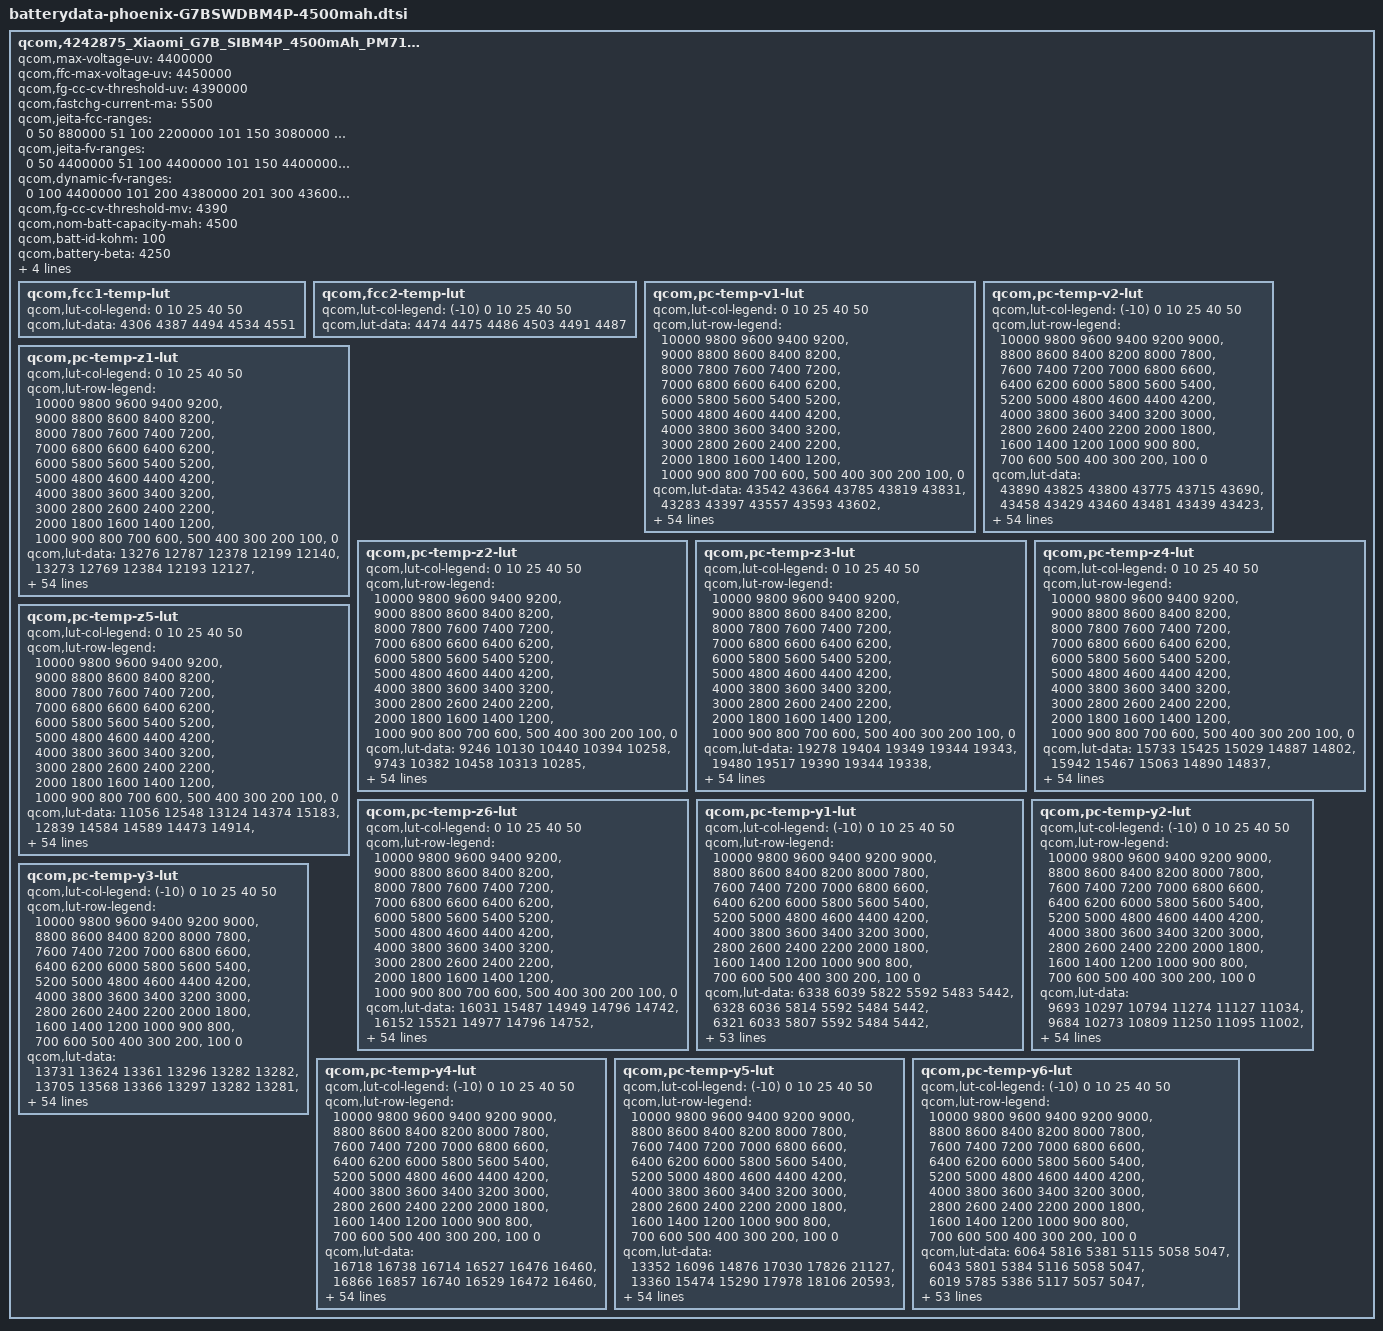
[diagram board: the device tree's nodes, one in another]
qcom,4242875_Xiaomi_G7B_SIBM4P_4500mAh_PM7150 {
	/* 4242875_Xiaomi_G7B_SIBM4P_4500mAh_PM7150_averaged_MasterSlave_Oct16th2019 */
	qcom,max-voltage-uv = <4400000>;
	qcom,ffc-max-voltage-uv = <4450000>;
	qcom,fg-cc-cv-threshold-uv = <4390000>;
	qcom,fastchg-current-ma = <5500>;
	qcom,jeita-fcc-ranges = <0  50  880000
				51  100  2200000
				101 150  3080000
				151 450  5500000
				451 580  2200000>;
	qcom,jeita-fv-ranges = <0   50  4400000
				51  100  4400000
				101 150  4400000
				151 450  4450000
				451 580  4100000>;
	qcom,dynamic-fv-ranges = <0    100  4400000
				101  200  4380000
				201  300  4360000
				301  400  4340000
				401  500  4340000>;
	qcom,fg-cc-cv-threshold-mv = <4390>;
	qcom,nom-batt-capacity-mah = <4500>;
	qcom,batt-id-kohm = <100>;
	qcom,battery-beta = <4250>;
	qcom,battery-therm-kohm = <100>;
	qcom,battery-type = "G7BSWDBM4P_4500mAh";
	qcom,qg-batt-profile-ver = <100>;
	mi,six-pin-battery;

	qcom,fcc1-temp-lut {
		qcom,lut-col-legend = <0 10 25 40 50>;
		qcom,lut-data = <4306 4387 4494 4534 4551>;
	};

	qcom,fcc2-temp-lut {
		qcom,lut-col-legend = <(-10) 0 10 25 40 50>;
		qcom,lut-data = <4474 4475 4486 4503 4491 4487>;
	};

	qcom,pc-temp-v1-lut {
		qcom,lut-col-legend = <0 10 25 40 50>;
		qcom,lut-row-legend = <10000 9800 9600 9400 9200>,
			<9000 8800 8600 8400 8200>,
			<8000 7800 7600 7400 7200>,
			<7000 6800 6600 6400 6200>,
			<6000 5800 5600 5400 5200>,
			<5000 4800 4600 4400 4200>,
			<4000 3800 3600 3400 3200>,
			<3000 2800 2600 2400 2200>,
			<2000 1800 1600 1400 1200>,
			<1000 900 800 700 600>,
			<500 400 300 200 100>,
			<0>;
		qcom,lut-data = <43542 43664 43785 43819 43831>,
			<43283 43397 43557 43593 43602>,
			<43023 43145 43301 43356 43370>,
			<42774 42905 43054 43118 43135>,
			<42543 42672 42815 42880 42901>,
			<42322 42440 42579 42642 42666>,
			<42109 42214 42345 42407 42433>,
			<41904 41997 42114 42173 42201>,
			<41707 41788 41888 41943 41970>,
			<41518 41585 41667 41715 41741>,
			<41337 41396 41453 41490 41514>,
			<41144 41210 41254 41271 41292>,
			<40932 41008 41060 41056 41073>,
			<40707 40787 40846 40847 40862>,
			<40457 40556 40605 40639 40657>,
			<40167 40305 40375 40437 40460>,
			<39932 40049 40169 40245 40271>,
			<39796 39875 39982 40063 40088>,
			<39694 39774 39831 39892 39913>,
			<39588 39678 39713 39742 39755>,
			<39483 39530 39577 39587 39596>,
			<39371 39341 39362 39388 39400>,
			<39227 39151 39117 39155 39168>,
			<39051 38939 38936 38961 38969>,
			<38893 38752 38794 38807 38812>,
			<38755 38656 38678 38675 38677>,
			<38636 38597 38586 38561 38561>,
			<38559 38544 38509 38462 38459>,
			<38508 38488 38433 38373 38367>,
			<38465 38435 38359 38292 38282>,
			<38425 38387 38293 38220 38206>,
			<38389 38341 38234 38156 38137>,
			<38355 38299 38183 38100 38076>,
			<38325 38259 38137 38048 38018>,
			<38296 38223 38100 38003 37966>,
			<38268 38189 38061 37958 37914>,
			<38241 38161 38024 37912 37860>,
			<38206 38126 37983 37863 37802>,
			<38152 38065 37925 37799 37731>,
			<38078 37971 37840 37714 37639>,
			<37992 37864 37738 37613 37533>,
			<37875 37738 37619 37496 37417>,
			<37735 37595 37480 37360 37285>,
			<37559 37427 37317 37199 37119>,
			<37393 37287 37173 37065 36989>,
			<37283 37218 37077 36979 36914>,
			<37246 37182 37054 36953 36891>,
			<37213 37156 37034 36938 36874>,
			<37183 37128 37020 36919 36854>,
			<37130 37077 36971 36861 36782>,
			<36913 36844 36716 36588 36480>,
			<36460 36391 36276 36143 36035>,
			<35875 35804 35691 35559 35450>,
			<35079 35004 34890 34760 34644>,
			<33819 33739 33631 33509 33380>,
			<30000 30000 30000 30000 30000>;
	};

	qcom,pc-temp-v2-lut {
		qcom,lut-col-legend = <(-10) 0 10 25 40 50>;
		qcom,lut-row-legend = <10000 9800 9600 9400 9200 9000>,
			<8800 8600 8400 8200 8000 7800>,
			<7600 7400 7200 7000 6800 6600>,
			<6400 6200 6000 5800 5600 5400>,
			<5200 5000 4800 4600 4400 4200>,
			<4000 3800 3600 3400 3200 3000>,
			<2800 2600 2400 2200 2000 1800>,
			<1600 1400 1200 1000 900 800>,
			<700 600 500 400 300 200>,
			<100 0>;
		qcom,lut-data = <43890 43825 43800 43775 43715 43690>,
			<43458 43429 43460 43481 43439 43423>,
			<43070 43068 43145 43203 43174 43165>,
			<42731 42744 42860 42941 42922 42916>,
			<42431 42450 42602 42696 42681 42676>,
			<42162 42188 42354 42457 42444 42440>,
			<41917 41967 42108 42219 42209 42206>,
			<41694 41765 41868 41984 41977 41974>,
			<41499 41541 41622 41755 41748 41745>,
			<41317 41282 41361 41532 41523 41519>,
			<41159 41076 41143 41314 41301 41295>,
			<41043 40975 41000 41105 41083 41078>,
			<40930 40893 40874 40900 40868 40863>,
			<40701 40700 40670 40687 40659 40657>,
			<40157 40199 40325 40464 40453 40455>,
			<39667 39766 40023 40248 40256 40261>,
			<39447 39610 39854 40036 40073 40078>,
			<39286 39502 39717 39837 39900 39902>,
			<39111 39354 39555 39677 39733 39733>,
			<38920 39150 39367 39551 39580 39576>,
			<38746 38931 39174 39408 39413 39406>,
			<38601 38703 38971 39189 39192 39189>,
			<38474 38479 38769 38944 38954 38953>,
			<38377 38335 38594 38754 38765 38766>,
			<38303 38241 38441 38598 38610 38613>,
			<38238 38170 38305 38464 38478 38482>,
			<38177 38114 38178 38350 38366 38369>,
			<38120 38067 38067 38250 38268 38269>,
			<38066 38024 37997 38160 38179 38178>,
			<38016 37983 37955 38078 38098 38093>,
			<37967 37945 37919 38005 38025 38017>,
			<37917 37908 37881 37934 37959 37950>,
			<37867 37870 37845 37870 37899 37890>,
			<37814 37831 37811 37817 37836 37825>,
			<37761 37790 37782 37773 37771 37755>,
			<37705 37746 37747 37728 37700 37678>,
			<37643 37697 37705 37679 37619 37579>,
			<37578 37642 37652 37626 37530 37469>,
			<37504 37576 37585 37560 37448 37378>,
			<37418 37496 37493 37479 37375 37305>,
			<37327 37404 37387 37387 37295 37229>,
			<37236 37296 37270 37280 37196 37131>,
			<37146 37175 37146 37159 37081 37016>,
			<37067 37052 37035 37016 36938 36876>,
			<36990 36937 36933 36907 36833 36777>,
			<36906 36849 36831 36850 36795 36739>,
			<36856 36811 36776 36834 36781 36729>,
			<36795 36768 36724 36810 36767 36711>,
			<36712 36715 36653 36770 36732 36675>,
			<36574 36619 36544 36674 36626 36539>,
			<36329 36409 36324 36397 36294 36173>,
			<35936 35996 35912 35895 35789 35654>,
			<35351 35372 35297 35233 35131 34976>,
			<34490 34490 34421 34324 34230 34043>,
			<33013 33050 32977 32889 32871 32634>,
			<28664 28265 27951 27826 28122 27845>;
	};

	qcom,pc-temp-z1-lut {
		qcom,lut-col-legend = <0 10 25 40 50>;
		qcom,lut-row-legend = <10000 9800 9600 9400 9200>,
			<9000 8800 8600 8400 8200>,
			<8000 7800 7600 7400 7200>,
			<7000 6800 6600 6400 6200>,
			<6000 5800 5600 5400 5200>,
			<5000 4800 4600 4400 4200>,
			<4000 3800 3600 3400 3200>,
			<3000 2800 2600 2400 2200>,
			<2000 1800 1600 1400 1200>,
			<1000 900 800 700 600>,
			<500 400 300 200 100>,
			<0>;
		qcom,lut-data = <13276 12787 12378 12199 12140>,
			<13273 12769 12384 12193 12127>,
			<13254 12761 12373 12177 12116>,
			<13239 12756 12365 12165 12107>,
			<13235 12752 12355 12158 12101>,
			<13231 12743 12349 12153 12096>,
			<13225 12733 12344 12148 12092>,
			<13215 12728 12338 12143 12088>,
			<13205 12726 12337 12141 12085>,
			<13196 12724 12335 12140 12084>,
			<13186 12718 12334 12139 12083>,
			<13174 12709 12337 12140 12082>,
			<13149 12695 12344 12142 12082>,
			<13117 12672 12341 12142 12082>,
			<13098 12655 12315 12135 12081>,
			<13082 12652 12298 12126 12081>,
			<13069 12652 12301 12126 12081>,
			<13053 12654 12307 12130 12083>,
			<13036 12665 12310 12133 12084>,
			<13031 12675 12313 12136 12085>,
			<13037 12677 12315 12138 12086>,
			<13044 12676 12320 12140 12086>,
			<13049 12678 12324 12142 12086>,
			<13055 12685 12325 12143 12086>,
			<13060 12693 12324 12144 12088>,
			<13067 12698 12324 12145 12092>,
			<13076 12702 12330 12147 12095>,
			<13081 12704 12341 12150 12098>,
			<13084 12700 12345 12153 12101>,
			<13084 12693 12346 12157 12105>,
			<13078 12693 12348 12161 12108>,
			<13071 12699 12350 12166 12112>,
			<13069 12705 12352 12170 12115>,
			<13079 12712 12355 12174 12119>,
			<13091 12722 12360 12177 12123>,
			<13098 12724 12364 12180 12126>,
			<13104 12721 12367 12184 12130>,
			<13111 12718 12369 12189 12133>,
			<13120 12723 12372 12193 12137>,
			<13132 12734 12378 12196 12142>,
			<13144 12747 12381 12198 12145>,
			<13157 12768 12382 12200 12146>,
			<13175 12777 12383 12202 12147>,
			<13200 12765 12384 12209 12150>,
			<13200 12768 12391 12211 12152>,
			<13202 12774 12394 12211 12153>,
			<13188 12765 12391 12217 12154>,
			<13202 12768 12396 12212 12157>,
			<13190 12771 12392 12218 12159>,
			<13183 12789 12404 12220 12164>,
			<13205 12801 12408 12229 12171>,
			<13209 12789 12412 12234 12175>,
			<13222 12805 12423 12238 12185>,
			<13253 12849 12449 12250 12195>,
			<13253 12849 12449 12250 12195>,
			<13253 12849 12449 12250 12195>;
	};

	qcom,pc-temp-z2-lut {
		qcom,lut-col-legend = <0 10 25 40 50>;
		qcom,lut-row-legend = <10000 9800 9600 9400 9200>,
			<9000 8800 8600 8400 8200>,
			<8000 7800 7600 7400 7200>,
			<7000 6800 6600 6400 6200>,
			<6000 5800 5600 5400 5200>,
			<5000 4800 4600 4400 4200>,
			<4000 3800 3600 3400 3200>,
			<3000 2800 2600 2400 2200>,
			<2000 1800 1600 1400 1200>,
			<1000 900 800 700 600>,
			<500 400 300 200 100>,
			<0>;
		qcom,lut-data = <9246 10130 10440 10394 10258>,
			<9743 10382 10458 10313 10285>,
			<10020 10406 10510 10375 10293>,
			<10186 10395 10520 10407 10299>,
			<10178 10383 10508 10390 10259>,
			<10161 10367 10492 10365 10182>,
			<10145 10347 10468 10345 10160>,
			<10128 10328 10442 10317 10159>,
			<10115 10307 10426 10291 10159>,
			<10112 10296 10414 10261 10150>,
			<10110 10301 10409 10235 10135>,
			<10109 10309 10411 10232 10137>,
			<10103 10312 10415 10233 10156>,
			<10097 10308 10425 10235 10167>,
			<10097 10305 10451 10229 10172>,
			<10102 10316 10467 10222 10185>,
			<10108 10341 10446 10226 10199>,
			<10120 10360 10412 10233 10216>,
			<10139 10371 10409 10243 10233>,
			<10158 10383 10431 10266 10252>,
			<10179 10405 10465 10304 10278>,
			<10200 10436 10544 10395 10325>,
			<10220 10451 10634 10549 10403>,
			<10238 10451 10639 10597 10435>,
			<10253 10448 10580 10482 10402>,
			<10265 10447 10543 10368 10363>,
			<10275 10444 10565 10412 10362>,
			<10285 10444 10598 10535 10372>,
			<10294 10452 10602 10570 10369>,
			<10303 10463 10585 10479 10262>,
			<10313 10470 10568 10390 10152>,
			<10324 10477 10555 10375 10148>,
			<10334 10484 10545 10366 10160>,
			<10342 10493 10544 10364 10175>,
			<10352 10503 10553 10358 10213>,
			<10364 10513 10566 10355 10263>,
			<10380 10523 10590 10393 10316>,
			<10392 10535 10623 10469 10372>,
			<10346 10552 10653 10511 10409>,
			<10270 10574 10686 10538 10437>,
			<10245 10586 10705 10553 10451>,
			<10206 10590 10700 10571 10446>,
			<10205 10596 10690 10589 10435>,
			<10308 10615 10690 10559 10422>,
			<10325 10729 10725 10533 10420>,
			<10264 12427 10738 10528 10390>,
			<10352 13610 10724 10514 10405>,
			<10335 24514 10727 10514 10436>,
			<10337 25623 10672 10546 10467>,
			<10253 30523 10765 10648 10590>,
			<10135 31150 10762 10507 10360>,
			<9996 22497 10725 10388 10261>,
			<9876 20729 10669 10368 10202>,
			<9706 16198 10668 10326 10167>,
			<9706 16198 10668 10326 10167>,
			<9706 16198 10668 10326 10167>;
	};

	qcom,pc-temp-z3-lut {
		qcom,lut-col-legend = <0 10 25 40 50>;
		qcom,lut-row-legend = <10000 9800 9600 9400 9200>,
			<9000 8800 8600 8400 8200>,
			<8000 7800 7600 7400 7200>,
			<7000 6800 6600 6400 6200>,
			<6000 5800 5600 5400 5200>,
			<5000 4800 4600 4400 4200>,
			<4000 3800 3600 3400 3200>,
			<3000 2800 2600 2400 2200>,
			<2000 1800 1600 1400 1200>,
			<1000 900 800 700 600>,
			<500 400 300 200 100>,
			<0>;
		qcom,lut-data = <19278 19404 19349 19344 19343>,
			<19480 19517 19390 19344 19338>,
			<19640 19554 19439 19369 19358>,
			<19734 19572 19453 19387 19376>,
			<19747 19581 19455 19393 19381>,
			<19755 19586 19456 19397 19384>,
			<19756 19589 19455 19397 19385>,
			<19752 19589 19454 19397 19385>,
			<19746 19585 19453 19398 19385>,
			<19739 19580 19453 19396 19383>,
			<19730 19574 19453 19393 19381>,
			<19724 19567 19449 19392 19379>,
			<19717 19563 19444 19390 19377>,
			<19711 19557 19441 19388 19375>,
			<19715 19553 19440 19383 19371>,
			<19729 19552 19438 19378 19366>,
			<19739 19549 19434 19376 19363>,
			<19727 19544 19428 19373 19361>,
			<19702 19532 19421 19371 19359>,
			<19684 19520 19413 19365 19354>,
			<19671 19523 19409 19360 19350>,
			<19663 19534 19415 19363 19352>,
			<19667 19539 19425 19373 19360>,
			<19682 19539 19425 19376 19364>,
			<19690 19537 19412 19365 19360>,
			<19689 19534 19404 19355 19356>,
			<19688 19528 19408 19367 19363>,
			<19685 19525 19415 19398 19386>,
			<19677 19526 19423 19408 19395>,
			<19669 19527 19436 19407 19391>,
			<19662 19528 19443 19404 19385>,
			<19655 19529 19442 19400 19380>,
			<19649 19530 19439 19393 19374>,
			<19643 19529 19435 19386 19369>,
			<19638 19528 19429 19380 19362>,
			<19632 19525 19424 19374 19357>,
			<19625 19521 19420 19370 19353>,
			<19619 19516 19416 19366 19350>,
			<19551 19512 19413 19364 19349>,
			<19453 19508 19410 19362 19351>,
			<19411 19504 19407 19361 19352>,
			<19302 19500 19405 19362 19351>,
			<19261 19495 19402 19363 19350>,
			<19261 19486 19397 19362 19355>,
			<19260 19395 19386 19355 19353>,
			<19261 19259 19380 19344 19342>,
			<19260 19258 19373 19343 19333>,
			<19260 19256 19372 19336 19330>,
			<19260 19256 19357 19334 19324>,
			<19261 19256 19351 19328 19321>,
			<19261 19256 19363 19345 19348>,
			<19262 19257 19353 19352 19347>,
			<19263 19256 19353 19352 19346>,
			<19265 19257 19345 19350 19348>,
			<19265 19257 19345 19350 19348>,
			<19265 19257 19345 19350 19348>;
	};

	qcom,pc-temp-z4-lut {
		qcom,lut-col-legend = <0 10 25 40 50>;
		qcom,lut-row-legend = <10000 9800 9600 9400 9200>,
			<9000 8800 8600 8400 8200>,
			<8000 7800 7600 7400 7200>,
			<7000 6800 6600 6400 6200>,
			<6000 5800 5600 5400 5200>,
			<5000 4800 4600 4400 4200>,
			<4000 3800 3600 3400 3200>,
			<3000 2800 2600 2400 2200>,
			<2000 1800 1600 1400 1200>,
			<1000 900 800 700 600>,
			<500 400 300 200 100>,
			<0>;
		qcom,lut-data = <15733 15425 15029 14887 14802>,
			<15942 15467 15063 14890 14837>,
			<15769 15427 15043 14879 14832>,
			<15585 15272 15011 14864 14825>,
			<15445 15137 14951 14842 14811>,
			<15317 15055 14896 14815 14791>,
			<15215 14988 14861 14794 14774>,
			<15133 14937 14832 14776 14759>,
			<15066 14895 14808 14759 14745>,
			<15013 14861 14786 14743 14730>,
			<14969 14834 14768 14730 14718>,
			<14932 14812 14751 14723 14710>,
			<14894 14790 14737 14718 14705>,
			<14866 14767 14730 14714 14701>,
			<14865 14753 14728 14709 14697>,
			<14879 14761 14728 14704 14693>,
			<14888 14778 14724 14697 14688>,
			<14870 14781 14715 14689 14683>,
			<14830 14750 14708 14683 14678>,
			<14800 14719 14696 14679 14674>,
			<14776 14723 14690 14676 14671>,
			<14762 14744 14722 14691 14682>,
			<14766 14770 14780 14737 14728>,
			<14786 14826 14815 14772 14760>,
			<14803 14880 14841 14797 14774>,
			<14825 14882 14852 14812 14783>,
			<14849 14865 14840 14795 14771>,
			<14852 14845 14814 14748 14730>,
			<14841 14828 14791 14722 14706>,
			<14828 14811 14768 14713 14701>,
			<14816 14796 14752 14707 14697>,
			<14804 14783 14745 14703 14692>,
			<14792 14772 14740 14700 14688>,
			<14782 14765 14736 14699 14686>,
			<14772 14759 14734 14699 14685>,
			<14761 14753 14733 14699 14685>,
			<14750 14745 14732 14699 14686>,
			<14744 14740 14731 14701 14688>,
			<14803 14740 14731 14703 14691>,
			<14895 14740 14732 14707 14696>,
			<14933 14739 14733 14710 14699>,
			<15032 14730 14725 14703 14694>,
			<15063 14719 14714 14693 14687>,
			<15040 14709 14708 14693 14688>,
			<14959 14753 14689 14685 14680>,
			<14935 14861 14670 14669 14662>,
			<14927 14855 14664 14662 14659>,
			<14922 14845 14654 14651 14645>,
			<14915 14839 14654 14635 14631>,
			<14908 14835 14655 14637 14628>,
			<14912 14843 14665 14650 14644>,
			<14931 14853 14680 14651 14652>,
			<14937 14855 14680 14652 14655>,
			<14948 14860 14690 14656 14653>,
			<14948 14860 14690 14656 14653>,
			<14948 14860 14690 14656 14653>;
	};

	qcom,pc-temp-z5-lut {
		qcom,lut-col-legend = <0 10 25 40 50>;
		qcom,lut-row-legend = <10000 9800 9600 9400 9200>,
			<9000 8800 8600 8400 8200>,
			<8000 7800 7600 7400 7200>,
			<7000 6800 6600 6400 6200>,
			<6000 5800 5600 5400 5200>,
			<5000 4800 4600 4400 4200>,
			<4000 3800 3600 3400 3200>,
			<3000 2800 2600 2400 2200>,
			<2000 1800 1600 1400 1200>,
			<1000 900 800 700 600>,
			<500 400 300 200 100>,
			<0>;
		qcom,lut-data = <11056 12548 13124 14374 15183>,
			<12839 14584 14589 14473 14914>,
			<14257 15825 16650 16270 17035>,
			<15340 16682 17658 17735 19058>,
			<16015 17518 18133 18382 19680>,
			<16561 18451 18535 18866 20077>,
			<17061 19358 18951 19297 20433>,
			<17511 20170 19405 19668 20801>,
			<17955 20938 20032 20046 21216>,
			<18525 21699 20904 20521 21858>,
			<19218 22565 21841 21031 22639>,
			<19655 23502 22707 21545 23287>,
			<19879 24510 23644 22147 23906>,
			<20215 26451 25049 22643 24219>,
			<21289 27848 27322 23160 24159>,
			<24199 27457 28586 23576 24053>,
			<26149 26479 27334 23678 24331>,
			<25546 26159 25369 23828 25450>,
			<24357 26639 25355 24164 26439>,
			<24031 27599 27623 24994 26967>,
			<24855 32686 30482 26155 27445>,
			<26480 44533 34092 27699 28148>,
			<31615 49587 37537 29601 29101>,
			<43051 46103 36541 29851 29359>,
			<49604 40932 28106 23819 24315>,
			<49892 36972 22357 17913 18468>,
			<48873 32431 22027 18919 18997>,
			<47154 30078 21862 22615 22551>,
			<43944 30060 22425 25555 25044>,
			<41044 30492 25895 27659 26148>,
			<39522 31334 29602 29386 27039>,
			<38371 33268 32362 30804 28112>,
			<37598 35492 34685 31976 29198>,
			<37058 37876 35783 32505 29775>,
			<36769 40303 36457 32765 30134>,
			<36702 41356 36728 32884 30340>,
			<36534 41818 36568 32582 30148>,
			<36419 42041 36158 31713 29535>,
			<33133 41928 35342 30536 28806>,
			<28219 41556 33241 28320 27762>,
			<25414 41095 31317 26654 26806>,
			<15223 39883 30372 26631 26069>,
			<11445 38160 29493 26920 25532>,
			<11459 35250 27773 26361 28019>,
			<11704 27193 28265 25056 28511>,
			<11738 11862 29748 22822 24185>,
			<11676 11811 27179 23192 20990>,
			<11667 11718 28492 22529 22454>,
			<11652 11698 22827 26082 25283>,
			<11679 11734 21687 23301 25607>,
			<11737 11738 22078 23239 29134>,
			<11637 11662 17741 22891 23789>,
			<11563 11576 17279 21759 20939>,
			<11472 11486 15810 19442 19552>,
			<11472 11486 15810 19442 19552>,
			<11472 11486 15810 19442 19552>;
	};

	qcom,pc-temp-z6-lut {
		qcom,lut-col-legend = <0 10 25 40 50>;
		qcom,lut-row-legend = <10000 9800 9600 9400 9200>,
			<9000 8800 8600 8400 8200>,
			<8000 7800 7600 7400 7200>,
			<7000 6800 6600 6400 6200>,
			<6000 5800 5600 5400 5200>,
			<5000 4800 4600 4400 4200>,
			<4000 3800 3600 3400 3200>,
			<3000 2800 2600 2400 2200>,
			<2000 1800 1600 1400 1200>,
			<1000 900 800 700 600>,
			<500 400 300 200 100>,
			<0>;
		qcom,lut-data = <16031 15487 14949 14796 14742>,
			<16152 15521 14977 14796 14752>,
			<16081 15498 14981 14799 14758>,
			<15995 15410 14976 14800 14762>,
			<15907 15329 14945 14793 14759>,
			<15811 15277 14913 14781 14750>,
			<15732 15232 14893 14771 14743>,
			<15668 15194 14877 14762 14736>,
			<15613 15162 14863 14754 14729>,
			<15565 15134 14851 14745 14722>,
			<15523 15110 14841 14738 14716>,
			<15482 15089 14831 14734 14711>,
			<15432 15065 14821 14731 14707>,
			<15391 15034 14814 14728 14704>,
			<15379 15015 14807 14721 14700>,
			<15375 15015 14802 14714 14695>,
			<15370 15017 14798 14710 14691>,
			<15349 15015 14793 14706 14688>,
			<15313 14999 14788 14702 14684>,
			<15290 14984 14780 14697 14680>,
			<15275 14989 14777 14694 14676>,
			<15266 15006 14795 14703 14682>,
			<15271 15025 14827 14729 14707>,
			<15290 15051 14840 14743 14722>,
			<15306 15073 14846 14749 14727>,
			<15318 15074 14848 14752 14730>,
			<15329 15065 14845 14751 14729>,
			<15330 15057 14840 14748 14725>,
			<15323 15052 14836 14745 14720>,
			<15315 15047 14834 14742 14716>,
			<15309 15044 14832 14738 14712>,
			<15302 15040 14830 14734 14708>,
			<15297 15038 14828 14730 14704>,
			<15292 15037 14825 14727 14700>,
			<15289 15036 14823 14723 14697>,
			<15287 15036 14821 14721 14694>,
			<15285 15035 14821 14720 14693>,
			<15284 15034 14820 14719 14692>,
			<15286 15035 14820 14719 14693>,
			<15289 15040 14821 14721 14696>,
			<15290 15042 14822 14722 14698>,
			<15292 15042 14820 14720 14696>,
			<15296 15042 14816 14718 14694>,
			<15303 15041 14813 14718 14697>,
			<15289 15027 14803 14711 14693>,
			<15281 15010 14794 14699 14679>,
			<15279 15007 14789 14696 14673>,
			<15278 15005 14785 14688 14666>,
			<15278 15005 14778 14680 14657>,
			<15283 15009 14779 14679 14655>,
			<15295 15019 14793 14696 14678>,
			<15312 15031 14798 14702 14683>,
			<15328 15041 14802 14705 14686>,
			<15352 15057 14809 14709 14690>,
			<15352 15057 14809 14709 14690>,
			<15352 15057 14809 14709 14690>;
	};

	qcom,pc-temp-y1-lut {
		qcom,lut-col-legend = <(-10) 0 10 25 40 50>;
		qcom,lut-row-legend = <10000 9800 9600 9400 9200 9000>,
			<8800 8600 8400 8200 8000 7800>,
			<7600 7400 7200 7000 6800 6600>,
			<6400 6200 6000 5800 5600 5400>,
			<5200 5000 4800 4600 4400 4200>,
			<4000 3800 3600 3400 3200 3000>,
			<2800 2600 2400 2200 2000 1800>,
			<1600 1400 1200 1000 900 800>,
			<700 600 500 400 300 200>,
			<100 0>;
		qcom,lut-data = <6338 6039 5822 5592 5483 5442>,
			<6328 6036 5814 5592 5484 5442>,
			<6321 6033 5807 5592 5484 5442>,
			<6317 6030 5801 5592 5485 5442>,
			<6315 6028 5797 5592 5485 5441>,
			<6313 6027 5797 5591 5484 5441>,
			<6316 6026 5801 5590 5482 5440>,
			<6322 6027 5807 5587 5479 5438>,
			<6322 6027 5807 5587 5478 5437>,
			<6316 6029 5799 5588 5477 5436>,
			<6311 6030 5793 5589 5476 5436>,
			<6312 6032 5794 5586 5475 5436>,
			<6317 6035 5796 5581 5474 5435>,
			<6320 6037 5798 5580 5472 5435>,
			<6328 6042 5802 5580 5469 5435>,
			<6334 6046 5806 5582 5468 5435>,
			<6333 6045 5810 5590 5471 5435>,
			<6331 6045 5814 5601 5476 5436>,
			<6330 6045 5815 5602 5477 5436>,
			<6333 6044 5814 5594 5475 5436>,
			<6336 6043 5812 5589 5474 5436>,
			<6331 6046 5811 5589 5475 5437>,
			<6322 6052 5810 5589 5478 5437>,
			<6318 6053 5810 5591 5479 5438>,
			<6309 6051 5810 5595 5480 5440>,
			<6302 6048 5809 5597 5481 5442>,
			<6305 6044 5807 5598 5483 5444>,
			<6310 6037 5803 5598 5485 5445>,
			<6312 6048 5801 5598 5488 5447>,
			<6309 6154 5800 5602 5490 5449>,
			<6307 6236 5799 5604 5492 5451>,
			<6313 6176 5802 5606 5494 5453>,
			<6327 6058 5806 5609 5495 5456>,
			<6329 6026 5807 5609 5497 5458>,
			<6306 6026 5806 5607 5500 5460>,
			<6285 6025 5804 5607 5502 5462>,
			<6286 6025 5803 5634 5502 5462>,
			<6291 6024 5801 5675 5502 5463>,
			<6292 6025 5800 5677 5502 5463>,
			<6288 6027 5799 5635 5503 5464>,
			<6283 6029 5798 5606 5504 5466>,
			<6281 6025 5802 5610 5505 5467>,
			<6279 6021 5805 5614 5507 5468>,
			<6288 6022 5803 5616 5511 5471>,
			<6303 6028 5805 5624 5516 5476>,
			<6333 6058 5818 5622 5519 5478>,
			<6353 6061 5823 5623 5521 5476>,
			<6355 6071 5823 5631 5517 5478>,
			<6354 6074 5829 5624 5520 5478>,
			<6364 6079 5833 5626 5518 5478>,
			<6378 6082 5835 5628 5522 5480>,
			<6393 6089 5840 5638 5527 5484>,
			<6410 6092 5854 5648 5534 5492>,
			<6422 6117 5865 5659 5545 5499>,
			<6422 6117 5865 5659 5545 5499>,
			<6422 6117 5865 5659 5545 5499>;
	};

	qcom,pc-temp-y2-lut {
		qcom,lut-col-legend = <(-10) 0 10 25 40 50>;
		qcom,lut-row-legend = <10000 9800 9600 9400 9200 9000>,
			<8800 8600 8400 8200 8000 7800>,
			<7600 7400 7200 7000 6800 6600>,
			<6400 6200 6000 5800 5600 5400>,
			<5200 5000 4800 4600 4400 4200>,
			<4000 3800 3600 3400 3200 3000>,
			<2800 2600 2400 2200 2000 1800>,
			<1600 1400 1200 1000 900 800>,
			<700 600 500 400 300 200>,
			<100 0>;
		qcom,lut-data = <9693 10297 10794 11274 11127 11034>,
			<9684 10273 10809 11250 11095 11002>,
			<9679 10258 10830 11225 11061 10970>,
			<9680 10251 10852 11198 11027 10939>,
			<9684 10250 10870 11172 10994 10909>,
			<9691 10251 10879 11144 10964 10883>,
			<9830 10320 10881 11116 10930 10857>,
			<10052 10434 10881 11087 10899 10834>,
			<10066 10465 10866 11063 10891 10823>,
			<9850 10445 10790 11043 10897 10818>,
			<9695 10435 10739 11022 10901 10813>,
			<9697 10483 10865 10994 10888 10792>,
			<9703 10559 11078 10969 10866 10763>,
			<9703 10566 11135 10976 10858 10760>,
			<9690 10395 11142 11043 10859 10783>,
			<9679 10292 11150 11117 10864 10806>,
			<9677 10362 11189 11169 10916 10829>,
			<9675 10438 11250 11222 11011 10859>,
			<9674 10449 11285 11294 11086 10884>,
			<9673 10402 11314 11400 11173 10929>,
			<9673 10329 11329 11455 11222 10973>,
			<9672 10119 11311 11426 11197 10999>,
			<9672 9791 11271 11376 11153 11021>,
			<9671 9694 11238 11354 11144 11042>,
			<9670 9693 11207 11341 11152 11065>,
			<9669 9692 11169 11336 11165 11085>,
			<9669 9689 11093 11351 11195 11098>,
			<9668 9684 10976 11380 11243 11110>,
			<9667 9680 10829 11407 11285 11141>,
			<9667 9677 10549 11451 11326 11232>,
			<9666 9674 10368 11473 11356 11295>,
			<9666 9672 10465 11469 11373 11286>,
			<9665 9670 10640 11461 11386 11270>,
			<9665 9668 10660 11459 11393 11271>,
			<9664 9667 10506 11459 11401 11301>,
			<9664 9665 10354 11457 11400 11317>,
			<9664 9664 10190 11429 11365 11274>,
			<9663 9663 9936 11376 11312 11204>,
			<9663 9663 9799 11325 11285 11172>,
			<9663 9662 9730 11269 11251 11155>,
			<9662 9662 9693 11208 11223 11144>,
			<9662 9661 9684 11140 11214 11135>,
			<9662 9661 9678 11075 11204 11120>,
			<9661 9660 9672 11010 11160 11086>,
			<9661 9660 9668 10944 11044 10988>,
			<9660 9659 9668 10949 10990 10842>,
			<9660 9659 9668 10969 10991 10875>,
			<9659 9659 9667 10942 11053 10876>,
			<9659 9659 9667 10952 11067 10897>,
			<9659 9658 9666 10931 11107 10913>,
			<9658 9658 9666 10880 10997 10833>,
			<9658 9658 9664 10760 10916 10802>,
			<9657 9657 9661 10650 10850 10695>,
			<9654 9656 9659 10554 10813 10547>,
			<9654 9656 9659 10554 10813 10547>,
			<9654 9656 9659 10554 10813 10547>;
	};

	qcom,pc-temp-y3-lut {
		qcom,lut-col-legend = <(-10) 0 10 25 40 50>;
		qcom,lut-row-legend = <10000 9800 9600 9400 9200 9000>,
			<8800 8600 8400 8200 8000 7800>,
			<7600 7400 7200 7000 6800 6600>,
			<6400 6200 6000 5800 5600 5400>,
			<5200 5000 4800 4600 4400 4200>,
			<4000 3800 3600 3400 3200 3000>,
			<2800 2600 2400 2200 2000 1800>,
			<1600 1400 1200 1000 900 800>,
			<700 600 500 400 300 200>,
			<100 0>;
		qcom,lut-data = <13731 13624 13361 13296 13282 13282>,
			<13705 13568 13366 13297 13282 13281>,
			<13674 13534 13370 13299 13282 13280>,
			<13644 13515 13374 13301 13283 13280>,
			<13619 13508 13377 13302 13283 13280>,
			<13604 13506 13379 13303 13283 13280>,
			<13601 13524 13378 13304 13284 13281>,
			<13599 13554 13377 13304 13284 13282>,
			<13584 13543 13379 13305 13285 13283>,
			<13527 13439 13390 13307 13286 13283>,
			<13488 13364 13397 13308 13287 13283>,
			<13499 13382 13381 13309 13287 13284>,
			<13519 13415 13354 13311 13287 13285>,
			<13520 13420 13350 13312 13288 13285>,
			<13494 13407 13361 13313 13290 13285>,
			<13472 13397 13369 13314 13292 13286>,
			<13470 13397 13365 13311 13294 13287>,
			<13470 13400 13355 13306 13295 13290>,
			<13470 13398 13348 13305 13295 13290>,
			<13472 13391 13343 13306 13294 13290>,
			<13472 13385 13338 13306 13293 13289>,
			<13467 13377 13332 13303 13290 13286>,
			<13460 13361 13327 13298 13285 13281>,
			<13460 13355 13322 13295 13282 13279>,
			<13470 13341 13319 13294 13281 13279>,
			<13484 13329 13315 13292 13280 13278>,
			<13498 13335 13302 13291 13280 13278>,
			<13513 13352 13286 13290 13280 13278>,
			<13532 13370 13279 13290 13280 13278>,
			<13556 13392 13269 13290 13280 13277>,
			<13583 13416 13262 13290 13280 13276>,
			<13610 13441 13275 13290 13280 13276>,
			<13638 13468 13301 13290 13280 13276>,
			<13666 13495 13315 13290 13280 13277>,
			<13694 13525 13322 13290 13281 13278>,
			<13723 13556 13328 13291 13281 13278>,
			<13755 13589 13336 13291 13280 13278>,
			<13789 13622 13345 13292 13279 13277>,
			<13823 13657 13353 13293 13279 13277>,
			<13856 13693 13361 13295 13281 13279>,
			<13892 13730 13371 13296 13282 13281>,
			<13933 13765 13391 13298 13283 13281>,
			<13981 13802 13421 13300 13283 13281>,
			<14042 13849 13459 13302 13281 13280>,
			<14119 13907 13519 13303 13282 13280>,
			<14199 13960 13526 13304 13287 13284>,
			<14236 13980 13541 13311 13289 13287>,
			<14296 14026 13586 13315 13293 13288>,
			<14360 14073 13615 13320 13294 13289>,
			<14424 14114 13637 13324 13294 13286>,
			<14494 14155 13653 13323 13290 13284>,
			<14575 14208 13685 13324 13292 13286>,
			<14762 14309 13785 13333 13297 13291>,
			<15258 14497 13954 13353 13304 13297>,
			<15258 14497 13954 13353 13304 13297>,
			<15258 14497 13954 13353 13304 13297>;
	};

	qcom,pc-temp-y4-lut {
		qcom,lut-col-legend = <(-10) 0 10 25 40 50>;
		qcom,lut-row-legend = <10000 9800 9600 9400 9200 9000>,
			<8800 8600 8400 8200 8000 7800>,
			<7600 7400 7200 7000 6800 6600>,
			<6400 6200 6000 5800 5600 5400>,
			<5200 5000 4800 4600 4400 4200>,
			<4000 3800 3600 3400 3200 3000>,
			<2800 2600 2400 2200 2000 1800>,
			<1600 1400 1200 1000 900 800>,
			<700 600 500 400 300 200>,
			<100 0>;
		qcom,lut-data = <16718 16738 16714 16527 16476 16460>,
			<16866 16857 16740 16529 16472 16460>,
			<16969 16947 16771 16530 16470 16460>,
			<17034 17011 16800 16530 16468 16459>,
			<17069 17048 16822 16531 16468 16458>,
			<17079 17061 16831 16531 16468 16458>,
			<17043 17033 16829 16530 16468 16458>,
			<16985 16987 16822 16528 16470 16457>,
			<17008 17010 16807 16528 16470 16457>,
			<17234 17213 16764 16531 16471 16459>,
			<17409 17372 16737 16533 16472 16461>,
			<17434 17400 16851 16533 16475 16462>,
			<17443 17417 17037 16534 16480 16464>,
			<17392 17376 17047 16538 16484 16467>,
			<17087 17086 16877 16554 16487 16471>,
			<16854 16869 16759 16572 16491 16476>,
			<16842 16886 16788 16587 16499 16480>,
			<16838 16921 16837 16601 16513 16486>,
			<16822 16923 16845 16623 16530 16497>,
			<16766 16858 16819 16658 16556 16521>,
			<16722 16778 16782 16676 16571 16536>,
			<16714 16702 16732 16633 16550 16522>,
			<16709 16631 16670 16562 16510 16494>,
			<16706 16616 16623 16526 16487 16477>,
			<16704 16629 16585 16504 16471 16464>,
			<16703 16641 16560 16494 16464 16458>,
			<16704 16641 16551 16493 16464 16458>,
			<16708 16639 16549 16493 16466 16459>,
			<16709 16639 16554 16494 16468 16461>,
			<16707 16638 16587 16497 16475 16467>,
			<16705 16638 16613 16498 16482 16475>,
			<16708 16643 16599 16496 16491 16485>,
			<16714 16653 16571 16492 16500 16495>,
			<16720 16664 16566 16491 16502 16497>,
			<16727 16674 16588 16493 16498 16497>,
			<16733 16686 16615 16496 16493 16497>,
			<16737 16698 16636 16500 16481 16484>,
			<16740 16711 16656 16504 16466 16463>,
			<16740 16715 16671 16507 16464 16458>,
			<16737 16714 16685 16509 16468 16465>,
			<16735 16712 16693 16513 16474 16473>,
			<16736 16705 16689 16525 16479 16478>,
			<16740 16692 16683 16536 16482 16481>,
			<16752 16682 16698 16540 16472 16462>,
			<16778 16679 16725 16549 16469 16453>,
			<16789 16681 16725 16537 16475 16470>,
			<16786 16686 16748 16552 16490 16493>,
			<16810 16712 16791 16579 16517 16524>,
			<16836 16750 16850 16620 16549 16554>,
			<16860 16790 16911 16655 16554 16536>,
			<16869 16808 16937 16642 16498 16477>,
			<16870 16795 16923 16609 16492 16473>,
			<16904 16785 16924 16633 16505 16479>,
			<17108 16815 16946 16678 16544 16514>,
			<17108 16815 16946 16678 16544 16514>,
			<17108 16815 16946 16678 16544 16514>;
	};

	qcom,pc-temp-y5-lut {
		qcom,lut-col-legend = <(-10) 0 10 25 40 50>;
		qcom,lut-row-legend = <10000 9800 9600 9400 9200 9000>,
			<8800 8600 8400 8200 8000 7800>,
			<7600 7400 7200 7000 6800 6600>,
			<6400 6200 6000 5800 5600 5400>,
			<5200 5000 4800 4600 4400 4200>,
			<4000 3800 3600 3400 3200 3000>,
			<2800 2600 2400 2200 2000 1800>,
			<1600 1400 1200 1000 900 800>,
			<700 600 500 400 300 200>,
			<100 0>;
		qcom,lut-data = <13352 16096 14876 17030 17826 21127>,
			<13360 15474 15290 17978 18106 20593>,
			<13447 15185 15983 18614 18175 19976>,
			<13600 15179 16744 18995 18100 19391>,
			<13806 15404 17360 19182 17953 18951>,
			<14053 15814 17618 19231 17800 18774>,
			<15822 18234 17597 18981 17388 18871>,
			<18507 21756 17534 18518 16833 19027>,
			<18632 21632 17557 18209 16680 18937>,
			<15770 16308 18248 17991 16729 18234>,
			<13708 12523 18795 17749 16710 17601>,
			<16748 15707 17329 17110 16206 17337>,
			<22047 21252 14958 16354 15512 17099>,
			<22553 22001 15386 16277 15456 16746>,
			<17545 18408 19171 16583 15936 16186>,
			<13801 15764 21744 16774 16264 15862>,
			<14178 17133 21018 15981 15957 16006>,
			<14952 19934 19716 14790 15460 16251>,
			<15137 21418 19632 14870 15384 16235>,
			<14981 22248 21122 16576 15595 15815>,
			<14712 22641 22558 18575 15941 15516>,
			<13917 20734 23206 20775 17440 16446>,
			<12731 16704 23685 22713 19520 18260>,
			<12417 14420 24027 22996 19918 19272>,
			<12444 13007 24388 22874 19662 19909>,
			<12467 12251 24577 22689 19393 20205>,
			<12447 12294 21665 22038 19123 19986>,
			<12403 12472 16387 21278 18758 19421>,
			<12421 12623 14222 21286 18463 18643>,
			<12746 12977 12980 21879 18188 17131>,
			<13106 13390 12360 22507 18051 16168>,
			<13306 13688 13355 23201 18340 16310>,
			<13515 13968 15231 23838 19055 16743>,
			<13651 14205 15900 23844 20033 17609>,
			<13820 14427 16039 23260 21751 20026>,
			<13996 14593 16164 22584 22798 21701>,
			<14147 14682 16252 21943 22093 21592>,
			<14297 14748 16179 21218 20857 21370>,
			<14326 14785 15884 20438 20605 21486>,
			<14132 14821 15136 19523 20862 22612>,
			<13856 14845 14546 18693 21061 23463>,
			<13566 14756 14482 18045 20751 22888>,
			<13304 14575 14469 17491 19991 22168>,
			<13307 14447 14228 17029 18422 21534>,
			<13325 14184 14173 16400 17616 20073>,
			<13441 14064 14382 17253 18539 17589>,
			<13650 14099 14348 17741 17728 17430>,
			<13788 14150 15026 17540 17902 16315>,
			<14107 14331 15534 17693 17283 16015>,
			<14295 14890 16234 18322 17264 15697>,
			<14384 15243 16609 18555 18425 16995>,
			<14392 14821 16037 18562 19647 18192>,
			<13929 14231 14733 18017 20757 20296>,
			<12550 13695 13603 18440 23765 24714>,
			<12550 13695 13603 18440 23765 24714>,
			<12550 13695 13603 18440 23765 24714>;
	};

	qcom,pc-temp-y6-lut {
		qcom,lut-col-legend = <(-10) 0 10 25 40 50>;
		qcom,lut-row-legend = <10000 9800 9600 9400 9200 9000>,
			<8800 8600 8400 8200 8000 7800>,
			<7600 7400 7200 7000 6800 6600>,
			<6400 6200 6000 5800 5600 5400>,
			<5200 5000 4800 4600 4400 4200>,
			<4000 3800 3600 3400 3200 3000>,
			<2800 2600 2400 2200 2000 1800>,
			<1600 1400 1200 1000 900 800>,
			<700 600 500 400 300 200>,
			<100 0>;
		qcom,lut-data = <6064 5816 5381 5115 5058 5047>,
			<6043 5801 5384 5116 5058 5047>,
			<6019 5785 5386 5117 5057 5047>,
			<5995 5770 5386 5118 5057 5046>,
			<5974 5757 5386 5118 5057 5046>,
			<5959 5748 5385 5118 5057 5046>,
			<5948 5744 5380 5117 5057 5047>,
			<5940 5741 5372 5116 5058 5047>,
			<5938 5734 5364 5116 5058 5048>,
			<5944 5720 5353 5117 5059 5048>,
			<5952 5712 5347 5117 5060 5049>,
			<5967 5730 5366 5118 5061 5050>,
			<5989 5762 5396 5118 5062 5051>,
			<5980 5756 5396 5120 5064 5052>,
			<5884 5668 5359 5125 5066 5054>,
			<5811 5603 5333 5130 5068 5055>,
			<5810 5610 5339 5133 5072 5058>,
			<5811 5624 5348 5135 5077 5060>,
			<5809 5626 5349 5140 5082 5064>,
			<5800 5603 5339 5150 5088 5071>,
			<5792 5578 5325 5156 5092 5074>,
			<5790 5558 5308 5142 5084 5068>,
			<5791 5540 5289 5117 5068 5057>,
			<5793 5536 5276 5106 5060 5050>,
			<5802 5543 5267 5099 5054 5046>,
			<5814 5553 5261 5096 5052 5044>,
			<5827 5566 5255 5095 5052 5044>,
			<5842 5585 5250 5096 5053 5044>,
			<5859 5605 5250 5096 5054 5045>,
			<5878 5629 5260 5098 5056 5046>,
			<5898 5654 5273 5100 5058 5048>,
			<5920 5682 5287 5100 5061 5051>,
			<5944 5711 5304 5100 5064 5054>,
			<5967 5741 5323 5101 5065 5056>,
			<5992 5772 5347 5102 5064 5056>,
			<6017 5804 5374 5105 5063 5057>,
			<6044 5837 5401 5107 5060 5053>,
			<6071 5869 5430 5110 5055 5046>,
			<6098 5900 5460 5113 5055 5045>,
			<6125 5930 5489 5117 5057 5049>,
			<6153 5959 5520 5121 5060 5053>,
			<6188 5987 5556 5129 5063 5054>,
			<6229 6016 5599 5137 5064 5055>,
			<6283 6052 5654 5145 5061 5049>,
			<6355 6100 5729 5157 5061 5048>,
			<6436 6150 5737 5153 5068 5056>,
			<6473 6171 5757 5165 5074 5064>,
			<6529 6215 5806 5179 5084 5074>,
			<6590 6264 5845 5197 5094 5084>,
			<6653 6310 5880 5211 5095 5077>,
			<6718 6350 5902 5209 5077 5059>,
			<6790 6394 5934 5207 5078 5060>,
			<6964 6475 6035 5238 5086 5066>,
			<7446 6647 6192 5288 5105 5082>,
			<7446 6647 6192 5288 5105 5082>,
			<7446 6647 6192 5288 5105 5082>;
	};

};
